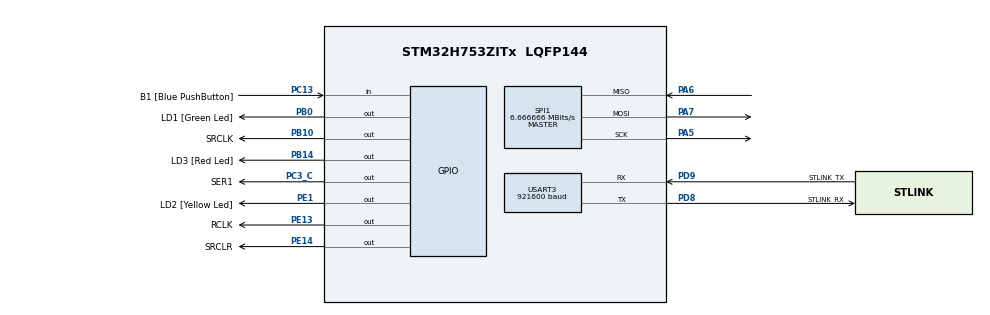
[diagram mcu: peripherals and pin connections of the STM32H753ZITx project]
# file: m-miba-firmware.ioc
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CORTEX_M7.CPU_DCache=Disabled
CORTEX_M7.CPU_ICache=Disabled
CORTEX_M7.MPU_Control=__NULL
Mcu.Family=STM32H7
Mcu.Name=STM32H753ZITx
Mcu.Package=LQFP144
NVIC.PriorityGroup=NVIC_PRIORITYGROUP_4
NVIC.TIM5_IRQn=true\:0\:0\:false\:false\:true\:true\:true\:true
PA5.Mode=Full_Duplex_Master
PA5.PinAttribute=Free
PA5.Signal=SPI1_SCK
PA6.Mode=Full_Duplex_Master
PA6.PinAttribute=Free
PA6.Signal=SPI1_MISO
PA7.Mode=Full_Duplex_Master
PA7.PinAttribute=Free
PA7.Signal=SPI1_MOSI
PB0.GPIO_Label=LD1 [Green Led]
PB0.PinAttribute=Free
PB0.Signal=GPIO_Output
PB10.GPIO_Label=SRCLK
PB10.GPIO_Speed=GPIO_SPEED_FREQ_VERY_HIGH
PB10.Signal=GPIO_Output
PB14.GPIO_Label=LD3 [Red Led]
PB14.Signal=GPIO_Output
PC13.GPIO_Label=B1 [Blue PushButton]
PC13.PinAttribute=Free
PC13.Signal=GPIO_Input
PC14-OSC32_IN\ (OSC32_IN).Mode=LSE-External-Oscillator
PC14-OSC32_IN\ (OSC32_IN).PinAttribute=Free
PC14-OSC32_IN\ (OSC32_IN).Signal=RCC_OSC32_IN
PC15-OSC32_OUT\ (OSC32_OUT).Mode=LSE-External-Oscillator
PC15-OSC32_OUT\ (OSC32_OUT).PinAttribute=Free
PC15-OSC32_OUT\ (OSC32_OUT).Signal=RCC_OSC32_OUT
PC3_C.GPIO_Label=SER1
PC3_C.GPIO_Speed=GPIO_SPEED_FREQ_VERY_HIGH
PC3_C.PinAttribute=Free
PC3_C.Signal=GPIO_Output
PD8.GPIO_Label=STLINK_RX
PD8.Mode=Asynchronous
PD8.Signal=USART3_TX
PD9.GPIO_Label=STLINK_TX
PD9.Mode=Asynchronous
PD9.Signal=USART3_RX
PE1.GPIO_Label=LD2 [Yellow Led]
PE1.GPIO_Speed=GPIO_SPEED_FREQ_LOW
PE1.Signal=GPIO_Output
PE13.GPIO_Label=RCLK
PE13.GPIO_Speed=GPIO_SPEED_FREQ_VERY_HIGH
PE13.Signal=GPIO_Output
PE14.GPIO_Label=SRCLR
PE14.GPIO_Speed=GPIO_SPEED_FREQ_VERY_HIGH
PE14.Signal=GPIO_Output
PH0-OSC_IN\ (PH0).Mode=HSE-External-Clock-Source
PH0-OSC_IN\ (PH0).PinAttribute=Free
PH0-OSC_IN\ (PH0).Signal=RCC_OSC_IN
PH1-OSC_OUT\ (PH1).PinAttribute=Free
PH1-OSC_OUT\ (PH1).Signal=RCC_OSC_OUT
ProjectManager.HeapSize=0x200
ProjectManager.StackSize=0x400
ProjectManager.TargetToolchain=STM32CubeIDE
RCC.ADCFreq_Value=129000000
RCC.APB1Freq_Value=120000000
RCC.APB2Freq_Value=120000000
RCC.APB3Freq_Value=120000000
RCC.APB4Freq_Value=120000000
RCC.CortexFreq_Value=480000000
RCC.D1PPRE=RCC_APB3_DIV2
RCC.D2PPRE1=RCC_APB1_DIV2
RCC.D2PPRE2=RCC_APB2_DIV2
RCC.D3PPRE=RCC_APB4_DIV2
RCC.DIVM1=4
RCC.DIVN1=60
RCC.DIVQ1=9
RCC.HCLKFreq_Value=240000000
RCC.HPRE=RCC_HCLK_DIV2
RCC.HSE_VALUE=8000000
RCC.PLL2FRACN=0
RCC.PLL3FRACN=0
RCC.PLLFRACN=0
RCC.SYSCLKFreq_VALUE=480000000
RCC.SYSCLKSource=RCC_SYSCLKSOURCE_PLLCLK
RCC.USBFreq_Value=106666666.66666667
SPI1.BaudRatePrescaler=SPI_BAUDRATEPRESCALER_16
SPI1.CLKPhase=SPI_PHASE_1EDGE
SPI1.CalculateBaudRate=6.666666 MBits/s
SPI1.DataSize=SPI_DATASIZE_8BIT
SPI1.Direction=SPI_DIRECTION_2LINES
SPI1.Mode=SPI_MODE_MASTER
SPI1.VirtualType=VM_MASTER
TIM3.Prescaler=240
TIM4.Prescaler=240
TIM5.AutoReloadPreload=TIM_AUTORELOAD_PRELOAD_ENABLE
TIM5.Period=2272
TIM5.Prescaler=240
USART3.AutoBaudRateEnableParam=UART_ADVFEATURE_AUTOBAUDRATE_DISABLE
USART3.BaudRate=921600
USART3.ClockPrescaler=PRESCALER_DIV1
USART3.DMADisableonRxErrorParam=ADVFEATURE_DMA_ENABLEONRXERROR
USART3.DataInvertParam=ADVFEATURE_DATAINV_DISABLE
USART3.FIFOMode=FIFOMODE_DISABLE
USART3.MSBFirstParam=ADVFEATURE_MSBFIRST_DISABLE
USART3.Mode=MODE_TX_RX
USART3.OneBitSampling=UART_ONE_BIT_SAMPLE_DISABLE
USART3.OverSampling=UART_OVERSAMPLING_8
USART3.OverrunDisableParam=ADVFEATURE_OVERRUN_ENABLE
USART3.Parity=PARITY_NONE
USART3.RXFIFOThreshold=RXFIFO_THRESHOLD_1EIGHTHFULL
USART3.RxPinLevelInvertParam=ADVFEATURE_RXINV_DISABLE
USART3.StopBits=STOPBITS_1
USART3.SwapParam=ADVFEATURE_SWAP_DISABLE
USART3.TXFIFOThreshold=TXFIFO_THRESHOLD_1EIGHTHFULL
USART3.TxPinLevelInvertParam=ADVFEATURE_TXINV_DISABLE
USART3.VirtualMode-Asynchronous=VM_ASYNC
USART3.WordLength=WORDLENGTH_8B
VP_MEMORYMAP_VS_MEMORYMAP.Mode=CurAppReg
VP_TIM3_VS_ClockSourceINT.Mode=Internal
VP_TIM4_VS_ClockSourceINT.Mode=Internal
VP_TIM5_VS_ClockSourceINT.Mode=Internal
board=NUCLEO-H753ZI

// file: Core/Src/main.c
/* USER CODE BEGIN Header */
/**
  ******************************************************************************
  * @file           : main.c
  * @brief          : Main program body
  ******************************************************************************
  * @attention
  *
  * Copyright (c) 2024 STMicroelectronics.
  * All rights reserved.
  *
  * This software is licensed under terms that can be found in the LICENSE file
  * in the root directory of this software component.
  * If no LICENSE file comes with this software, it is provided AS-IS.
  *
  ******************************************************************************
  */
/* USER CODE END Header */
#include "main.h"
#include "memorymap.h"
#include "spi.h"
#include "tim.h"
#include "usart.h"
#include "gpio.h"

/* USER CODE BEGIN Includes */
#include "printing.h"
#include "m-miba_main.h"

/* USER CODE END Includes */

void SystemClock_Config(void);

int main(void)
{

  /* MCU Configuration--------------------------------------------------------*/

  /* Reset of all peripherals, Initializes the Flash interface and the Systick. */
  HAL_Init();

  /* Configure the system clock */
  SystemClock_Config();

  /* Initialize all configured peripherals */
  MX_GPIO_Init();
  MX_USART3_UART_Init();
  MX_SPI1_Init();
  MX_TIM3_Init();
  MX_TIM4_Init();
  MX_TIM5_Init();
  /* USER CODE BEGIN 2 */

  mmiba_main();  // Main file

  /* USER CODE END 2 */

  /* Infinite loop */
  /* USER CODE BEGIN WHILE */
  while (1)
  {
	  printf("hello\n\r");
    /* USER CODE END WHILE */

  }
}

void SystemClock_Config(void)
{
  RCC_OscInitTypeDef RCC_OscInitStruct = {0};
  RCC_ClkInitTypeDef RCC_ClkInitStruct = {0};

  /** Supply configuration update enable
  */
  HAL_PWREx_ConfigSupply(PWR_LDO_SUPPLY);

  /** Configure the main internal regulator output voltage
  */
  __HAL_PWR_VOLTAGESCALING_CONFIG(PWR_REGULATOR_VOLTAGE_SCALE1);

  while(!__HAL_PWR_GET_FLAG(PWR_FLAG_VOSRDY)) {}

  __HAL_RCC_SYSCFG_CLK_ENABLE();
  __HAL_PWR_VOLTAGESCALING_CONFIG(PWR_REGULATOR_VOLTAGE_SCALE0);

  while(!__HAL_PWR_GET_FLAG(PWR_FLAG_VOSRDY)) {}

  /** Initializes the RCC Oscillators according to the specified parameters
  * in the RCC_OscInitTypeDef structure.
  */
  RCC_OscInitStruct.OscillatorType = RCC_OSCILLATORTYPE_HSI;
  RCC_OscInitStruct.HSIState = RCC_HSI_DIV1;
  RCC_OscInitStruct.HSICalibrationValue = RCC_HSICALIBRATION_DEFAULT;
  RCC_OscInitStruct.PLL.PLLState = RCC_PLL_ON;
  RCC_OscInitStruct.PLL.PLLSource = RCC_PLLSOURCE_HSI;
  RCC_OscInitStruct.PLL.PLLM = 4;
  RCC_OscInitStruct.PLL.PLLN = 60;
  RCC_OscInitStruct.PLL.PLLP = 2;
  RCC_OscInitStruct.PLL.PLLQ = 9;
  RCC_OscInitStruct.PLL.PLLR = 2;
  RCC_OscInitStruct.PLL.PLLRGE = RCC_PLL1VCIRANGE_3;
  RCC_OscInitStruct.PLL.PLLVCOSEL = RCC_PLL1VCOWIDE;
  RCC_OscInitStruct.PLL.PLLFRACN = 0;
  if (HAL_RCC_OscConfig(&RCC_OscInitStruct) != HAL_OK)
  {
    Error_Handler();
  }

  /** Initializes the CPU, AHB and APB buses clocks
  */
  RCC_ClkInitStruct.ClockType = RCC_CLOCKTYPE_HCLK|RCC_CLOCKTYPE_SYSCLK
                              |RCC_CLOCKTYPE_PCLK1|RCC_CLOCKTYPE_PCLK2
                              |RCC_CLOCKTYPE_D3PCLK1|RCC_CLOCKTYPE_D1PCLK1;
  RCC_ClkInitStruct.SYSCLKSource = RCC_SYSCLKSOURCE_PLLCLK;
  RCC_ClkInitStruct.SYSCLKDivider = RCC_SYSCLK_DIV1;
  RCC_ClkInitStruct.AHBCLKDivider = RCC_HCLK_DIV2;
  RCC_ClkInitStruct.APB3CLKDivider = RCC_APB3_DIV2;
  RCC_ClkInitStruct.APB1CLKDivider = RCC_APB1_DIV2;
  RCC_ClkInitStruct.APB2CLKDivider = RCC_APB2_DIV2;
  RCC_ClkInitStruct.APB4CLKDivider = RCC_APB4_DIV2;

  if (HAL_RCC_ClockConfig(&RCC_ClkInitStruct, FLASH_LATENCY_4) != HAL_OK)
  {
    Error_Handler();
  }
}

void Error_Handler(void)
{
  __disable_irq();
  while (1)
  {
  }
}
